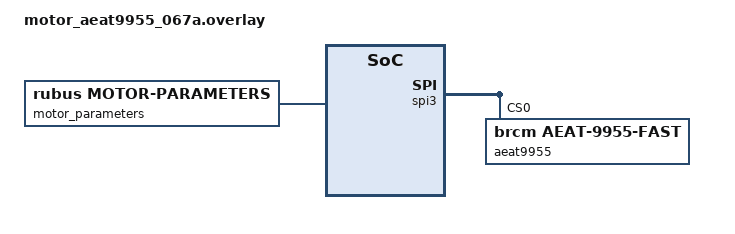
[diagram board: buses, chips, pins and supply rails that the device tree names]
/*
 * Motor profile overlay for AEAT-9955 encoder setup (0.67 A class motor).
 *
 * Usage:
 *   west build ... -- \
 *     -DDTC_OVERLAY_FILE="app/boards/smartstepper_v2.overlay;app/configs/motor_aeat9955_067a.overlay"
 *
 * Notes:
 * - This mirrors the current AEAT-based motor configuration from
 *   smartstepper_v2 overlay so it can be selected explicitly as a profile.
 * - Keep board pin/peripheral wiring in the board overlay.
 */

/ {
	aliases {
		/delete-property/ encoder0;
		/* Use AEAT-9955 fast frontend for control-loop encoder input. */
		encoder1 = &aeat9955;
	};

	user_parameters: user_parameters {
		compatible = "rubus,user-parameters";
		nominal_voltage-mv = <24000>;
		pwm-frequency-hz = <20000>;
		control-loop-frequency-hz = <20000>;
		current-loop-bandwidth-hz = <150>;
		current-command-ramp-ms = <100>;
		offset-pole-hz = <300>;
		/*
		 * AEAT-9955 positive direction is clockwise looking from the back
		 * of the motor. The motor/front convention used by the controller
		 * therefore requires inversion.
		 */
		encoder-direction-sign = <(-1)>;
		/*
		 * This hybrid stepper did not reliably move to the commanded
		 * alignment vector at 67 mA. 150 mA caused an overcurrent during
		 * polarity reversal on the AEAT setup, so use a conservative
		 * intermediate value with a longer dwell.
		 */
		align-current-ma = <100>;
		align-duration-ms = <200>;
		brake-current-ma = <1000>;
		max-modulation-index-mpu = <950>;
		roverl-est-current-ma = <100>;
		roverl-est-freq-hz = <250>;
		roverl-est-settling-ms = <50>;
		roverl-est-duration-ms = <5000>;
		rs-est-current-ma = <100>;
		rs-est-rampup-ms = <1000>;
		rs-est-duration-ms = <1000>;
		commission-electrical-rs-current-ma = <100>;
		commission-electrical-current-limit-ma = <100>;
		commission-electrical-demod-pulse-mv = <450>;
		commission-electrical-max-pulse-mv = <500>;
		rls-excitation-current-ma = <100>;
		velocity-max-hz = <50>;
		velocity-max-accel-hz-per-s = <10>;
		velocity-initial-hz = <0>;
		commission-standard-min-auto-iq-ma = <250>;
		commission-validate-current-default-iq-ma = <80>;
	};

	motor_parameters: motor_parameters {
		compatible = "rubus,motor-parameters";
		inductance-d-uh = <3400>;
		inductance-q-uh = <3400>;
		resistance-mohms = <5600>;
		/* Boot/fallback only; commissioning estimates runtime psi_f/Kt. */
		flux_linkage_uvphz = <17675>;
		pole-pairs = <50>;
		max-current-ma = <670>;
		/* Boot/fallback only; commissioning estimates runtime inertia. */
		inertia-mgcm2 = <9000>;
		max-speed-hz = <50>;
	};

	fault_detection: fault_detection {
		compatible = "rubus,fault-detection";
		encoder-fault-threshold = <100>;
		/* 120% of 0.67 A current limit. */
		overcurrent-threshold-ma = <800>;
	};

};

&spi3 {
	compatible = "rubus,stm32-rt-spi";
	status = "okay";
	spi-clock-frequency = <DT_FREQ_M(4)>;
	max-frame-len = <8>;
	cs-mode = "hardware";
	spi-cpha;
	fifo-enable;

	aeat9955: aeat9955@0 {
		compatible = "brcm,aeat-9955-fast";
		reg = <0>;
		pipeline-delay-samples = <0>;
		spi4-mode = "spi4-8-crc16";
		status = "okay";
	};
};
